# SKEAZ1284 register map
Vendor: Freescale Semiconductor, Inc.; Series: Kinetis_EA; File version: 1.6
CPU: CM0PLUS r0p0, little endian, no MPU, no FPU, VTOR, 2 interrupt priority bits
Registers are 8-bit, read-write, reset 0x0 unless marked. A register's access mark holds for its fields unless they carry their own. Offsets are from the block's base; [hi:lo] are bit positions; {n}, {i} and the like mark numbered series; 'fields as' and 'values as' point back to an identical list.

## PORT — Port control and interrupts
Base 0x40049000; register names take the prefix PORT_
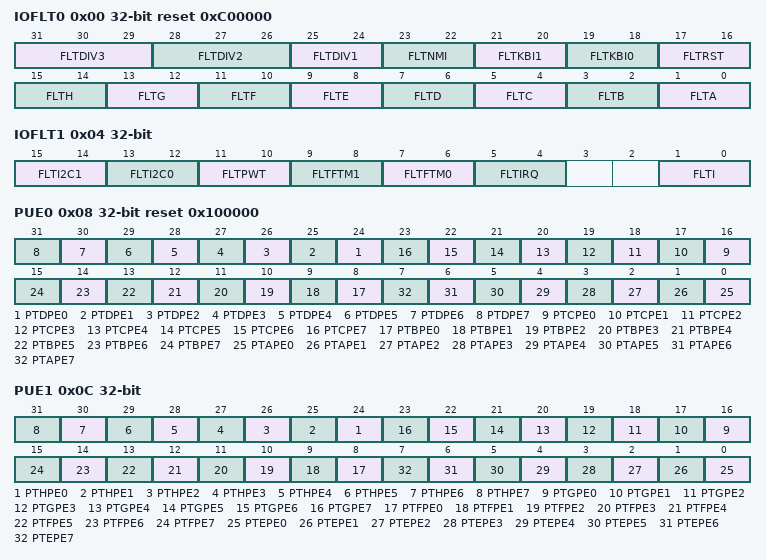
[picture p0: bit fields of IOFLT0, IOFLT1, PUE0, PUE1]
0x00 IOFLT0 32-bit reset 0xC00000 — Port Filter Register 0
  [31:29] FLTDIV3 — Filter Division Set 3
    0=LPOCLK; 1=LPOCLK/2; 2=LPOCLK/4; 3=LPOCLK/8; 4=LPOCLK/16; 5=LPOCLK/32; 6=LPOCLK/64; 7=LPOCLK/128
  [28:26] FLTDIV2 — Filter Division Set 2
    0=BUSCLK/32; 1=BUSCLK/64; 2=BUSCLK/128; 3=BUSCLK/256; 4=BUSCLK/512; 5=BUSCLK/1024; 6=BUSCLK/2048; 7=BUSCLK/4096
  [25:24] FLTDIV1 — Filter Division Set 1
    0=BUSCLK/2; 1=BUSCLK/4; 2=BUSCLK/8; 3=BUSCLK/16
  [23:22] FLTNMI — Filter Selection for Input from NMI
    0=No filter; 1=Selects FLTDIV1, and will switch to FLTDIV3 in Stop mode automatically; 2=Selects FLTDIV2, and will switch to FLTDIV3 in Stop mode automatically; 3=FLTDIV3
  [21:20] FLTKBI1 — Filter Selection for Input from KBI1
    values as FLTNMI
  [19:18] FLTKBI0 — Filter selection for Input from KBI0
    values as FLTNMI
  [17:16] FLTRST — Filter Selection for Input from RESET/IRQ
    values as FLTNMI
  [15:14] FLTH — Filter Selection for Input from PTH
    0=BUSCLK; 1=FLTDIV1; 2=FLTDIV2; 3=FLTDIV3
  [13:12] FLTG — Filter Selection for Input from PTG
    0=BUSCLK; 1=FLTDIV1; 2=FLTDIV2; 3=FLTDIV3
  [11:10] FLTF — Filter Selection for Input from PTF
    0=BUSCLK; 1=FLTDIV1; 2=FLTDIV2; 3=FLTDIV3
  [9:8] FLTE — Filter Selection for Input from PTD
    0=BUSCLK; 1=FLTDIV1; 2=FLTDIV2; 3=FLTDIV3
  [7:6] FLTD — Filter Selection for Input from PTD
    0=BUSCLK; 1=FLTDIV1; 2=FLTDIV2; 3=FLTDIV3
  [5:4] FLTC — Filter Selection for Input from PTC
    0=BUSCLK; 1=FLTDIV1; 2=FLTDIV2; 3=FLTDIV3
  [3:2] FLTB — Filter Selection for Input from PTB
    0=BUSCLK; 1=FLTDIV1; 2=FLTDIV2; 3=FLTDIV3
  [1:0] FLTA — Filter Selection for Input from PTA
    0=BUSCLK; 1=FLTDIV1; 2=FLTDIV2; 3=FLTDIV3
0x04 IOFLT1 32-bit — Port Filter Register 1
  [15:14] FLTI2C1 — Filter Selection For Input from SCL1/SDA1
    0=No filter; 1=Select FLTDIV1; 2=Select FLTDIV2; 3=Select BUSCLK
  [13:12] FLTI2C0 — Filter Selection For Input from SCL0/SDA0
    values as FLTI2C1
  [11:10] FLTPWT — Filter Selection For Input from PWT_IN1/PWT_IN0
    0=No filter; 1=Select FLTDIV1; 2=Select FLTDIV2; 3=Select FLTDIV3
  [9:8] FLTFTM1 — Filter Selection For Input from FTM1CH0/FTM1CH1
    values as FLTPWT
  [7:6] FLTFTM0 — Filter Selection For Input from FTM0CH0/FTM0CH1
    values as FLTPWT
  [5:4] FLTIRQ — Filter Selection for Input from IRQ
    values as IOFLT0.FLTNMI
  [1:0] FLTI — Filter Selection for Input from PTI
    0=BUSCLK; 1=FLTDIV1; 2=FLTDIV2; 3=FLTDIV3
0x08 PUE0 32-bit reset 0x100000 — Port Pullup Enable Register 0
  [n+24] PTDPE{n} (n=0..7) — Pull Enable for Port D Bit {n}
    0=Pullup is disabled for port D bit {n}; 1=Pullup is enabled for port D bit {n}
  [n+16] PTCPE{n} (n=0..7) — Pull Enable for Port C Bit {n}
    0=Pullup is disabled for port C bit {n}; 1=Pullup is enabled for port C bit {n}
  [n+8] PTBPE{n} (n=0..7) — Pull Enable for Port B Bit {n}
    0=Pullup is disabled for port B bit {n}; 1=Pullup is enabled for port B bit {n}
  [n] PTAPE{n} (n=0..7) — Pull Enable for Port A Bit {n}
    0=Pullup is disabled for port A bit {n}; 1=Pullup is enabled for port A bit {n}
0x0C PUE1 32-bit — Port Pullup Enable Register 1
  [n+24] PTHPE{n} (n=0..7) — Pull Enable for Port H Bit {n}
    0=Pullup is disabled for port H bit {n}; 1=Pullup is enabled for port H bit {n}
  [n+16] PTGPE{n} (n=0..7) — Pull Enable for Port G Bit {n}
    0=Pullup is disabled for port G bit {n}; 1=Pullup is enabled for port G bit {n}
  [n+8] PTFPE{n} (n=0..7) — Pull Enable for Port F Bit {n}
    0=Pullup is disabled for port F bit {n}; 1=Pullup is enabled for port F bit {n}
  [n] PTEPE{n} (n=0..7) — Pull Enable for Port E Bit {n}
    0=Pullup is disabled for port E bit {n}; 1=Pullup is enabled for port E bit {n}
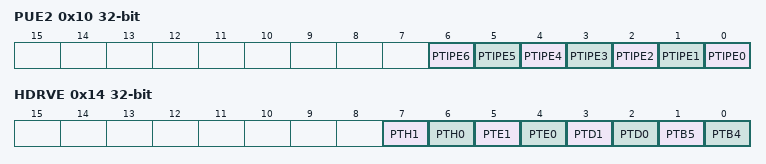
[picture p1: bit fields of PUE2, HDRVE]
0x10 PUE2 32-bit — Port Pullup Enable Register 2
  [n] PTIPE{n} (n=0..6) — Pull Enable for Port I Bit {n}
    0=Pullup is disabled for port I bit {n}; 1=Pullup is enabled for port I bit {n}
0x14 HDRVE 32-bit — Port High Drive Enable Register
  [7] PTH1 — High Current Drive Capability of PTH1
    0=PTH1 is disabled to offer high current drive capability; 1=PTH1 is enabled to offer high current drive capability
  [6] PTH0 — High Current Drive Capability of PTH0
    0=PTH0 is disabled to offer high current drive capability; 1=PTH0 is enabled to offer high current drive capability
  [5] PTE1 — High Current Drive Capability of PTE1
    0=PTE1 is disabled to offer high current drive capability; 1=PTE1 is enabled to offer high current drive capability
  [4] PTE0 — High Current Drive Capability of PTE0
    0=PTE0 is disabled to offer high current drive capability; 1=PTE0 is enable to offer high current drive capability
  [3] PTD1 — High Current Drive Capability of PTD1
    0=PTD1 is disabled to offer high current drive capability; 1=PTD1 is enable to offer high current drive capability
  [2] PTD0 — High Current Drive Capability of PTD0
    0=PTD0 is disabled to offer high current drive capability; 1=PTD0 is enabled to offer high current drive capability
  [1] PTB5 — High Current Drive Capability of PTB5
    0=PTB5 is disabled to offer high current drive capability; 1=PTB5 is enabled to offer high current drive capability
  [0] PTB4 — High Current Drive Capability of PTB4
    0=PTB4 is disabled to offer high current drive capability; 1=PTB4 is enabled to offer high current drive capability
